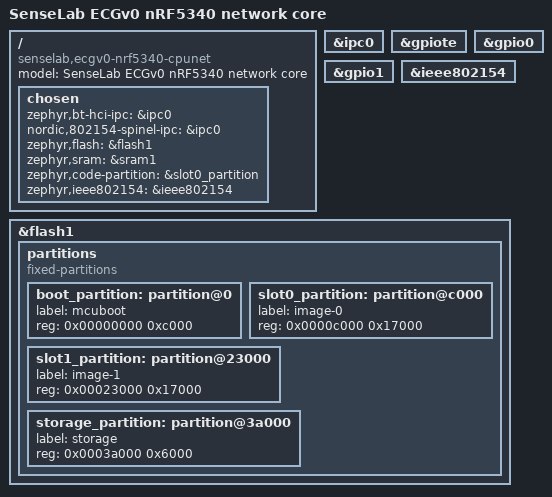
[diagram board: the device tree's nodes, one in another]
/dts-v1/;

#include <nordic/nrf5340_cpunet_qkaa.dtsi>

/ {
	model = "SenseLab ECGv0 nRF5340 network core";
	compatible = "senselab,ecgv0-nrf5340-cpunet";

	chosen {
		zephyr,bt-hci-ipc = &ipc0;
		nordic,802154-spinel-ipc = &ipc0;
		zephyr,flash = &flash1;
		zephyr,sram = &sram1;
		zephyr,code-partition = &slot0_partition;
		zephyr,ieee802154 = &ieee802154;
	};
};

&ipc0 { status = "okay"; };
&gpiote { status = "okay"; };
&gpio0 { status = "okay"; };
&gpio1 { status = "okay"; };
&ieee802154 { status = "okay"; };

&flash1 {
	partitions {
		compatible = "fixed-partitions";
		#address-cells = <1>;
		#size-cells = <1>;

		boot_partition: partition@0 {
			label = "mcuboot";
			reg = <0x00000000 0xc000>;
		};

		slot0_partition: partition@c000 {
			label = "image-0";
			reg = <0x0000c000 0x17000>;
		};

		slot1_partition: partition@23000 {
			label = "image-1";
			reg = <0x00023000 0x17000>;
		};

		storage_partition: partition@3a000 {
			label = "storage";
			reg = <0x0003a000 0x6000>;
		};
	};
};

#include <common/nordic/nrf5340_shared_sram_partition.dtsi>
